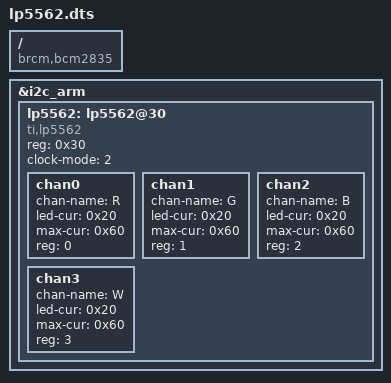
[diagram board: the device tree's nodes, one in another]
// Device tree overlay for the TI LP5562 RGBW LED driver at I2C1 address 0x30
// (front LED of the MNTD Goldspot / RAK Hotspot Miner V2). Reconstructed from the
// property names in the stock firmware's lp5562.dtbo and the leds-lp55xx binding.
// Build: dtc -@ -I dts -O dtb -o /boot/firmware/overlays/lp5562.dtbo lp5562.dts
// Use:   dtoverlay=lp5562   -> /sys/class/leds/{R,G,B,W}/brightness
/dts-v1/;
/plugin/;

/ {
    compatible = "brcm,bcm2835";

    fragment@0 {
        target = <&i2c_arm>;
        __overlay__ {
            #address-cells = <1>;
            #size-cells = <0>;
            status = "okay";

            lp5562: lp5562@30 {
                compatible = "ti,lp5562";
                reg = <0x30>;
                clock-mode = /bits/ 8 <2>;   /* internal clock */
                #address-cells = <1>;
                #size-cells = <0>;

                chan0 { chan-name = "R"; led-cur = /bits/ 8 <0x20>; max-cur = /bits/ 8 <0x60>; reg = <0>; };
                chan1 { chan-name = "G"; led-cur = /bits/ 8 <0x20>; max-cur = /bits/ 8 <0x60>; reg = <1>; };
                chan2 { chan-name = "B"; led-cur = /bits/ 8 <0x20>; max-cur = /bits/ 8 <0x60>; reg = <2>; };
                chan3 { chan-name = "W"; led-cur = /bits/ 8 <0x20>; max-cur = /bits/ 8 <0x60>; reg = <3>; };
            };
        };
    };
};
